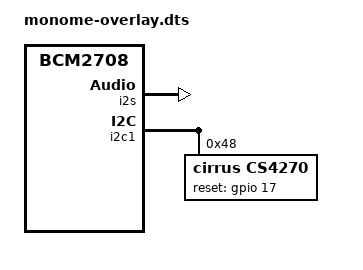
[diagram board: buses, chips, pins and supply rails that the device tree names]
// Definitions for monome
/dts-v1/;
/plugin/;

/ {
	compatible = "brcm,bcm2708";

	fragment@0 {
		target = <&sound>;
		__overlay__ {
			compatible = "monome";
			i2s-controller = <&i2s>;
			status = "okay";
		};
	};

	fragment@1 {
		target = <&i2s>;
		__overlay__ {
			status = "okay";
		};
	};

	fragment@2 {
		target = <&i2c1>;
		__overlay__ {
			#address-cells = <1>;
			#size-cells = <0>;
			status = "okay";

			cs4270: cs4270@48 {
				#sound-dai-cells = <0>;
				compatible = "cirrus,cs4270";
				reg = <0x48>;
				reset-gpio = <&gpio 17 2>;
				status="okay";

				reset_pin {
				  gpio-hog;
				  gpios = <17>;
				  output-high;
				  line-name = "reset-gpio";
			       };
                        };
		};
	};	   
};
